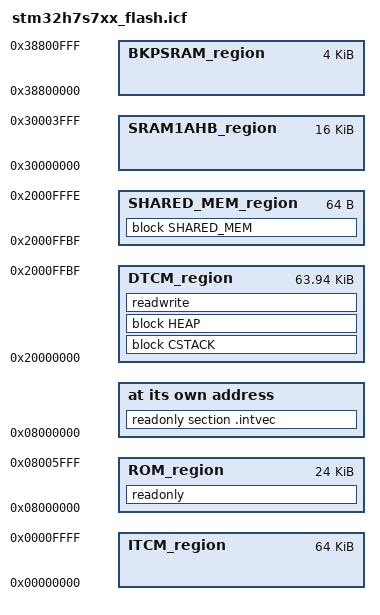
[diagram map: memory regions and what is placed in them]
/*###ICF### Section handled by ICF editor, don't touch! ****/
/*-Editor annotation file-*/
/* IcfEditorFile="$TOOLKIT_DIR$\config\ide\IcfEditor\cortex_v1_0.xml" */
/*-Specials-*/
define symbol CODE_OFFSET = 0x0; /* STiROT_iLoader offset from STiROT_Config.xml */
define symbol CODE_SIZE = 0x6000; 	/* STiROT_iLoader size from STiROT_Config.xml */

define symbol __ICFEDIT_intvec_start__                     = 0x08000000 + CODE_OFFSET;
/*-Memory Regions-*/
define symbol __ICFEDIT_region_ROM_start__                 = 0x08000000 + CODE_OFFSET;
define symbol __ICFEDIT_region_ROM_end__                   = 0x08000000 + CODE_OFFSET + CODE_SIZE - 1;
define symbol __ICFEDIT_region_SRAM1AXI_start__            = 0x24000000;
define symbol __ICFEDIT_region_SRAM1AXI_end__              = 0x2401FFFF;
define symbol __ICFEDIT_region_SRAM2AXI_start__            = 0x24020000;
define symbol __ICFEDIT_region_SRAM2AXI_end__              = 0x2403FF00;
define symbol __ICFEDIT_region_SRAM3AXI_start__            = 0x24040000;
define symbol __ICFEDIT_region_SRAM3AXI_end__              = 0x2405FFFF;
define symbol __ICFEDIT_region_SRAM4AXI_start__            = 0x24060000;
define symbol __ICFEDIT_region_SRAM4AXI_end__              = 0x2407FFFF;

/*-Sizes-*/
define symbol __ICFEDIT_size_cstack__                      = 0x800;
define symbol __ICFEDIT_size_heap__                        = 0x0;

/**** End of ICF editor section. ###ICF###*/

define symbol          __region_ITCM_start__               = 0x00000000;
define symbol          __region_ITCM_end__                 = 0x0000FFFF;
define symbol          __region_DTCM_start__               = 0x20000000;
define symbol          __region_DTCM_end__                 = 0x2000FFBF; /* last 0x40 reserved for SHARED_MEM */
define symbol          __region_SRAM1AHB_start__           = 0x30000000;
define symbol          __region_SRAM1AHB_end__             = 0x30003FFF;
define symbol          __region_SRAM2AHB_start__           = 0x30004000;
define symbol          __region_SRAM2AHB_end__             = 0x30007FFF;
define symbol          __region_BKPSRAM_start__            = 0x38800000;
define symbol          __region_BKPSRAM_end__              = 0x38800FFF;

/*-Shared Memory Region-*/
define  symbol __region_SHARED_MEM_size__         = 0x40;
define  exported symbol __region_SHARED_MEM_start__        = __region_DTCM_end__;
define  exported symbol __region_SHARED_MEM_end__          = __region_SHARED_MEM_start__ + __region_SHARED_MEM_size__;

define memory mem with size = 4G;
define region ROM_region            = mem:[from __ICFEDIT_region_ROM_start__        to __ICFEDIT_region_ROM_end__];
define region ITCM_region           = mem:[from __region_ITCM_start__               to __region_ITCM_end__];
define region DTCM_region           = mem:[from __region_DTCM_start__               to __region_DTCM_end__];
define region SRAM1AHB_region       = mem:[from __region_SRAM1AHB_start__           to __region_SRAM1AHB_end__];
define region BKPSRAM_region        = mem:[from __region_BKPSRAM_start__            to __region_BKPSRAM_end__];

define region SHARED_MEM_region     = mem:[from __region_SHARED_MEM_start__ size __region_SHARED_MEM_size__];


define block CSTACK    with alignment = 8, size = __ICFEDIT_size_cstack__   { };
define block HEAP      with alignment = 8, size = __ICFEDIT_size_heap__     { };

define block SHARED_MEM { section .shared_mem };

initialize by copy { readwrite };
do not initialize { section .noinit, section .shared_mem };

place at address mem:__ICFEDIT_intvec_start__ { readonly section .intvec };

place in ROM_region                 { readonly };
place in DTCM_region                { block CSTACK, block HEAP, readwrite };
place in SHARED_MEM_region          { block SHARED_MEM};
